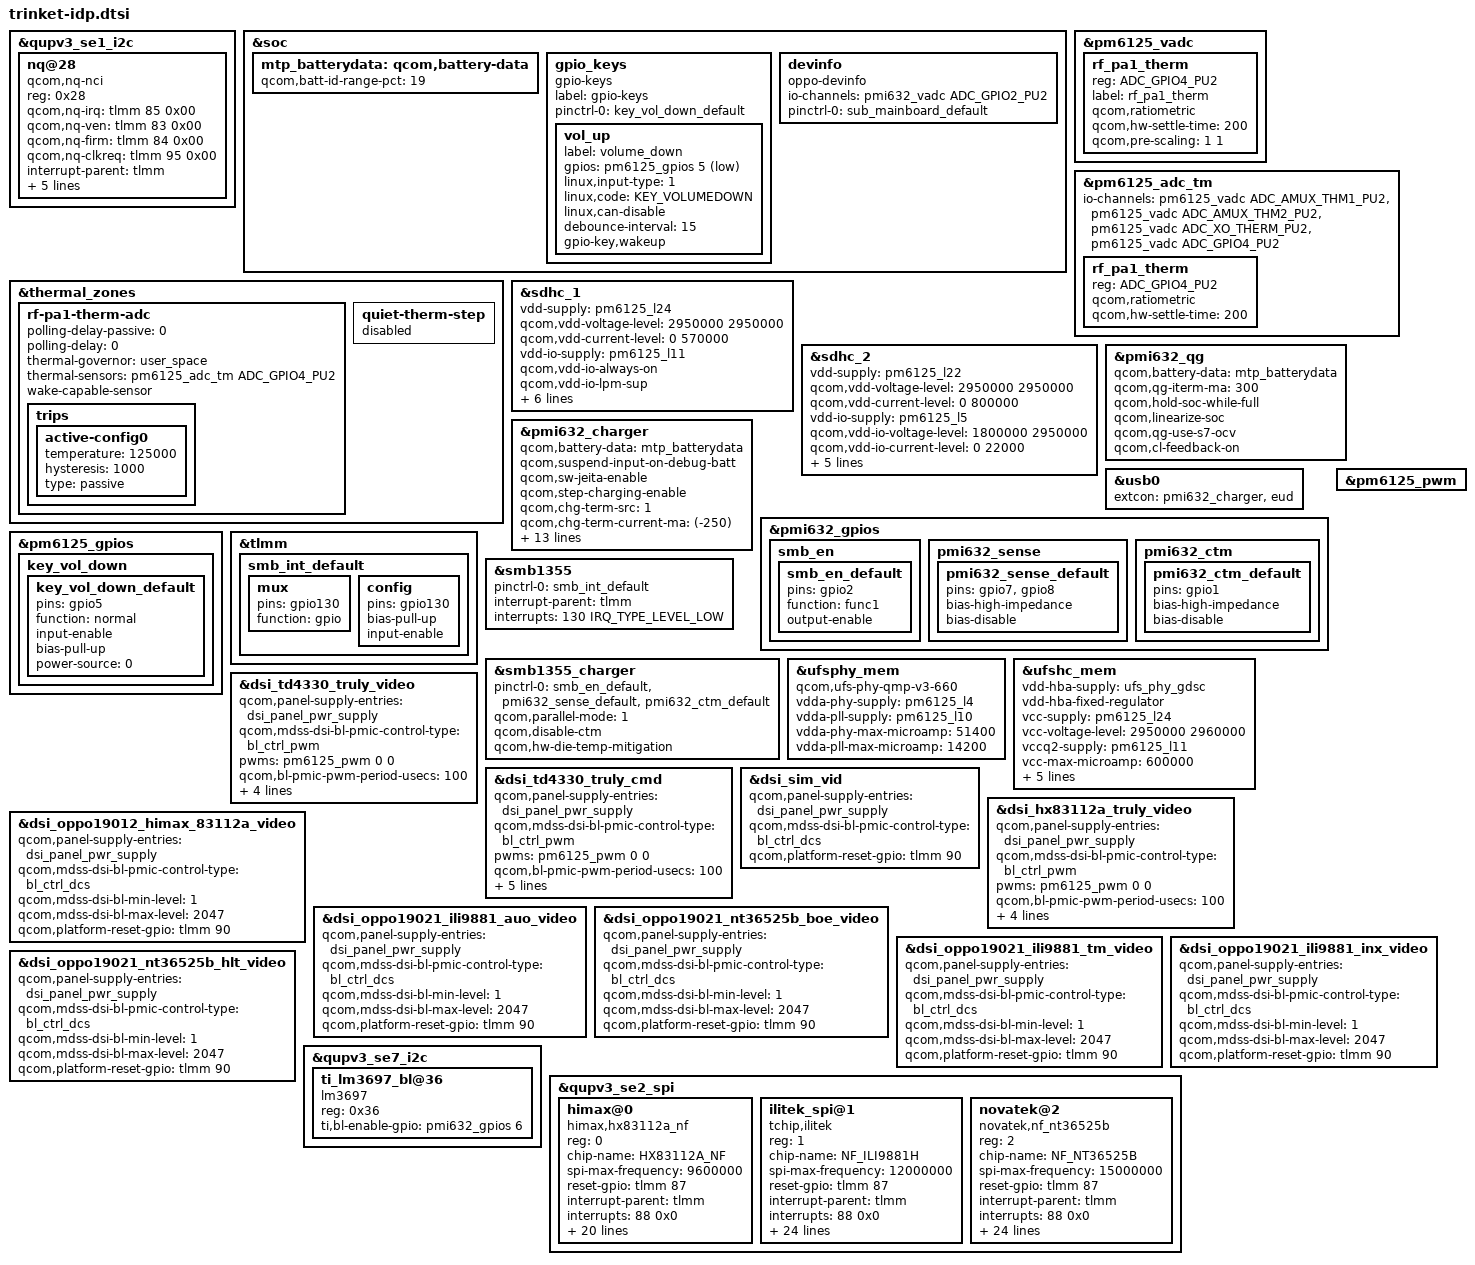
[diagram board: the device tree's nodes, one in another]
/*
 * Copyright (c) 2018-2019, The Linux Foundation. All rights reserved.
 *
 * This program is free software; you can redistribute it and/or modify
 * it under the terms of the GNU General Public License version 2 and
 * only version 2 as published by the Free Software Foundation.
 *
 * This program is distributed in the hope that it will be useful,
 * but WITHOUT ANY WARRANTY; without even the implied warranty of
 * MERCHANTABILITY or FITNESS FOR A PARTICULAR PURPOSE.  See the
 * GNU General Public License for more details.
 */
#include <dt-bindings/gpio/gpio.h>
#include <dt-bindings/input/input.h>
#include <dt-bindings/iio/qcom,spmi-vadc.h>
#include "trinket-thermal-overlay.dtsi"
#include "trinket-sde-display.dtsi"
#include <dt-bindings/clock/qcom,gcc-trinket.h>
#include "trinket-camera-sensor-idp.dtsi"

&qupv3_se1_i2c {
	status = "ok";
	#include "smb1355.dtsi"
};

&soc {
	mtp_batterydata: qcom,battery-data {
//#ifndef VENDOR_EDIT
//		qcom,batt-id-range-pct = <15>;
//#else
        qcom,batt-id-range-pct = <19>;
//#endif
//#ifndef VENDOR_EDIT
//		#include "qg-batterydata-ascent-3450mah.dtsi"
//		#include "qg-batterydata-mlp356477-2800mah.dtsi"
//#else
		#include "oppo_battery_4910mah_68k_pmi632_atl.dtsi"
		#include "oppo_battery_5000mah_470k_pmi632_sdi.dtsi"
		#include "oppo_battery_5000mah_15k_pmi632_cl.dtsi"
//#endif
	};
};

&pm6125_vadc {
	rf_pa1_therm {
		reg = <ADC_GPIO4_PU2>;
		label = "rf_pa1_therm";
		qcom,ratiometric;
		qcom,hw-settle-time = <200>;
		qcom,pre-scaling = <1 1>;
	};
};

&pm6125_adc_tm {
	io-channels = <&pm6125_vadc ADC_AMUX_THM1_PU2>,
			<&pm6125_vadc ADC_AMUX_THM2_PU2>,
			<&pm6125_vadc ADC_XO_THERM_PU2>,
			<&pm6125_vadc ADC_GPIO4_PU2>;

	rf_pa1_therm {
		reg = <ADC_GPIO4_PU2>;
		qcom,ratiometric;
		qcom,hw-settle-time = <200>;
	};
};

&thermal_zones {
	rf-pa1-therm-adc {
		polling-delay-passive = <0>;
		polling-delay = <0>;
		thermal-governor = "user_space";
		thermal-sensors = <&pm6125_adc_tm ADC_GPIO4_PU2>;
		wake-capable-sensor;
		trips {
			active-config0 {
				temperature = <125000>;
				hysteresis = <1000>;
				type = "passive";
			};
		};
	};

	quiet-therm-step {
		status = "disabled";
	};
};

&qupv3_se1_i2c {
	status = "ok";
	nq@28 {
		compatible = "qcom,nq-nci";
		reg = <0x28>;
		qcom,nq-irq = <&tlmm 85 0x00>;
		qcom,nq-ven = <&tlmm 83 0x00>;
		qcom,nq-firm = <&tlmm 84 0x00>;
		qcom,nq-clkreq = <&tlmm 95 0x00>;
		interrupt-parent = <&tlmm>;
		interrupts = <85 0>;
		interrupt-names = "nfc_irq";
		pinctrl-names = "nfc_active", "nfc_suspend";
		pinctrl-0 = <&nfc_int_active &nfc_enable_active
				&nfc_clk_req_active>;
		pinctrl-1 = <&nfc_int_suspend &nfc_enable_suspend
				&nfc_clk_req_suspend>;
	};
};

&sdhc_1 {
	vdd-supply = <&pm6125_l24>;
	qcom,vdd-voltage-level = <2950000 2950000>;
	qcom,vdd-current-level = <0 570000>;

	vdd-io-supply = <&pm6125_l11>;
	qcom,vdd-io-always-on;
	qcom,vdd-io-lpm-sup;
	qcom,vdd-io-voltage-level = <1800000 1800000>;
	qcom,vdd-io-current-level = <0 325000>;

	pinctrl-names = "active", "sleep";
	pinctrl-0 = <&sdc1_clk_on &sdc1_cmd_on &sdc1_data_on
					&sdc1_rclk_on>;
	pinctrl-1 = <&sdc1_clk_off &sdc1_cmd_off &sdc1_data_off
					&sdc1_rclk_off>;

	status = "ok";
};

&sdhc_2 {
	vdd-supply = <&pm6125_l22>;
	qcom,vdd-voltage-level = <2950000 2950000>;
	qcom,vdd-current-level = <0 800000>;

	vdd-io-supply = <&pm6125_l5>;
	qcom,vdd-io-voltage-level = <1800000 2950000>;
	qcom,vdd-io-current-level = <0 22000>;

	pinctrl-names = "active", "sleep";
	pinctrl-0 = <&sdc2_clk_on  &sdc2_cmd_on &sdc2_data_on &sdc2_cd_on>;
	pinctrl-1 = <&sdc2_clk_off &sdc2_cmd_off &sdc2_data_off &sdc2_cd_off>;

	cd-gpios = <&tlmm 98 GPIO_ACTIVE_LOW>;

	status = "ok";
};

&pmi632_qg {
	qcom,battery-data = <&mtp_batterydata>;
	qcom,qg-iterm-ma = <300>;
	qcom,hold-soc-while-full;
	qcom,linearize-soc;
	qcom,qg-use-s7-ocv;
//#ifdef VENDOR_EDIT
	qcom,cl-feedback-on;
//#endif
};

&pmi632_charger {
	qcom,battery-data = <&mtp_batterydata>;
	qcom,suspend-input-on-debug-batt;
	qcom,sw-jeita-enable;
	qcom,step-charging-enable;
	qcom,chg-term-src = <1>;
	qcom,chg-term-current-ma = <(-250)>;
	qcom,chg-term-base-current-ma = <(-200)>;
	/* SMB1355 only */
	qcom,sec-charger-config = <2>;
	dpdm-supply = <&qusb_phy0>;
	qcom,charger-temp-max = <800>;
	qcom,smb-temp-max = <800>;
	qcom,auto-recharge-soc = <98>;
// #ifdef VENDOR_EDIT
    	// qcom,flash-disable-soc = <10>;
// #else
    	qcom,flash-disable-soc = <1>;
// #endif
	qcom,hw-die-temp-mitigation;
	qcom,hw-connector-mitigation;
	qcom,connector-internal-pull-kohm = <100>;
	qcom,float-option = <1>;
	qcom,thermal-mitigation = <3000000 2500000
			2000000 1500000 1000000 500000>;
};

&usb0 {
	extcon = <&pmi632_charger>, <&eud>;
};

&pmi632_gpios {
	smb_en {
		smb_en_default: smb_en_default {
			pins = "gpio2";
			function = "func1";
			output-enable;
		};
	};

	pmi632_sense {
		/* GPIO 7 and 8 are external-sense pins for PMI632 */
		pmi632_sense_default: pmi632_sense_default {
			pins = "gpio7", "gpio8";
			bias-high-impedance;	/* disable the GPIO */
			bias-disable;		/* no-pull */
		};
	};

	pmi632_ctm {
		/* Disable GPIO1 for h/w base mitigation */
		pmi632_ctm_default: pmi632_ctm_default {
			pins = "gpio1";
			bias-high-impedance;	/* disable the GPIO */
			bias-disable;		/* no-pull */
		};
	};
};

&pm6125_gpios {
	//#ifndef VENDOR_EDIT
	//key_vol_up {
	//	key_vol_up_default: key_vol_up_default {
	//		pins = "gpio5";
	//		function = "normal";
	//		input-enable;
	//		bias-pull-up;
	//		power-source = <0>;
	//	};
	//};
	//#else
	key_vol_down {
		key_vol_down_default: key_vol_down_default {
			pins = "gpio5";
			function = "normal";
			input-enable;
			bias-pull-up;
			power-source = <0>;
		};
	};
	//#endif
};

&soc {
	gpio_keys {
		compatible = "gpio-keys";
		label = "gpio-keys";

		pinctrl-names = "default";

		//#ifndef VENDOR_EDIT
		//pinctrl-0 = <&key_vol_up_default>;
		//vol_up {
		//	label = "volume_up";
		//	gpios = <&pm6125_gpios 5 GPIO_ACTIVE_LOW>;
		//	linux,input-type = <1>;
		//	linux,code = <KEY_VOLUMEUP>;
		//	linux,can-disable;
		//	debounce-interval = <15>;
		//	gpio-key,wakeup;
		//};
		//#else
		pinctrl-0 = <&key_vol_down_default>;
		vol_up {
			label = "volume_down";
			gpios = <&pm6125_gpios 5 GPIO_ACTIVE_LOW>;
			linux,input-type = <1>;
			linux,code = <KEY_VOLUMEDOWN>;
			linux,can-disable;
			debounce-interval = <15>;
			gpio-key,wakeup;
		};
		//#endif
	};

	/*ifdef VENDOR_EDIT*/
	devinfo {
		compatible = "oppo-devinfo";
		io-channel-names = "sub_adc_gpio3";
		io-channels = <&pmi632_vadc ADC_GPIO2_PU2>;
		pinctrl-names = "default";
		pinctrl-0 = <&sub_mainboard_default>;
	};
	/*endif*/
};

&tlmm {
	smb_int_default: smb_int_default {
		mux {
			pins = "gpio130";
			function = "gpio";
		};
		config {
			pins = "gpio130";
			bias-pull-up;
			input-enable;
		};
	};
};

&smb1355 {
	pinctrl-names = "default";
	pinctrl-0 = <&smb_int_default>;
	interrupt-parent = <&tlmm>;
	interrupts = <130 IRQ_TYPE_LEVEL_LOW>;
	status = "ok";
};

&smb1355_charger {
	pinctrl-names = "default";
	pinctrl-0 = <&smb_en_default &pmi632_sense_default &pmi632_ctm_default>;
	qcom,parallel-mode = <1>;
	qcom,disable-ctm;
	qcom,hw-die-temp-mitigation;
	status = "ok";
};

&ufsphy_mem {
	compatible = "qcom,ufs-phy-qmp-v3-660";

	vdda-phy-supply = <&pm6125_l4>; /* 0.9v */
	vdda-pll-supply = <&pm6125_l10>; /* 1.8v */
	vdda-phy-max-microamp = <51400>;
	vdda-pll-max-microamp = <14200>;

	status = "ok";
};

&ufshc_mem {
	vdd-hba-supply = <&ufs_phy_gdsc>;
	vdd-hba-fixed-regulator;
	vcc-supply = <&pm6125_l24>;
	vcc-voltage-level = <2950000 2960000>;
	vccq2-supply = <&pm6125_l11>;
	vcc-max-microamp = <600000>;
	vccq2-max-microamp = <600000>;

	qcom,vddp-ref-clk-supply = <&pm6125_l18>;
	qcom,vddp-ref-clk-max-microamp = <100>;
	qcom,vddp-ref-clk-min-uV = <1200000>;
	qcom,vddp-ref-clk-max-uV = <1232000>;

	status = "ok";
};

&pm6125_pwm {
	status = "ok";
};

&dsi_td4330_truly_video {
	qcom,panel-supply-entries = <&dsi_panel_pwr_supply>;
	qcom,mdss-dsi-bl-pmic-control-type = "bl_ctrl_pwm";
	pwms = <&pm6125_pwm 0 0>;
	qcom,bl-pmic-pwm-period-usecs = <100>;
	qcom,mdss-dsi-bl-min-level = <1>;
	qcom,mdss-dsi-bl-max-level = <4095>;
	qcom,platform-reset-gpio = <&tlmm 90 0>;
	qcom,platform-bklight-en-gpio = <&pmi632_gpios 6 0>;
};

&dsi_td4330_truly_cmd {
	qcom,panel-supply-entries = <&dsi_panel_pwr_supply>;
	qcom,mdss-dsi-bl-pmic-control-type = "bl_ctrl_pwm";
	pwms = <&pm6125_pwm 0 0>;
	qcom,bl-pmic-pwm-period-usecs = <100>;
	qcom,mdss-dsi-bl-min-level = <1>;
	qcom,mdss-dsi-bl-max-level = <4095>;
	qcom,platform-te-gpio = <&tlmm 89 0>;
	qcom,platform-reset-gpio = <&tlmm 90 0>;
	qcom,platform-bklight-en-gpio = <&pmi632_gpios 6 0>;
};

&dsi_sim_vid {
	qcom,panel-supply-entries = <&dsi_panel_pwr_supply>;
	qcom,mdss-dsi-bl-pmic-control-type = "bl_ctrl_dcs";
	qcom,platform-reset-gpio = <&tlmm 90 0>;
};

&dsi_hx83112a_truly_video {
	qcom,panel-supply-entries = <&dsi_panel_pwr_supply>;
	qcom,mdss-dsi-bl-pmic-control-type = "bl_ctrl_pwm";
	pwms = <&pm6125_pwm 0 0>;
	qcom,bl-pmic-pwm-period-usecs = <100>;
	qcom,mdss-dsi-bl-min-level = <1>;
	qcom,mdss-dsi-bl-max-level = <4095>;
	qcom,platform-reset-gpio = <&tlmm 90 0>;
	qcom,platform-bklight-en-gpio = <&pmi632_gpios 6 0>;
};


//ifdef VENDOR_EDIT
&dsi_oppo19012_himax_83112a_video {
	qcom,panel-supply-entries = <&dsi_panel_pwr_supply>;
	qcom,mdss-dsi-bl-pmic-control-type = "bl_ctrl_dcs";
	qcom,mdss-dsi-bl-min-level = <1>;
	qcom,mdss-dsi-bl-max-level = <2047>;
	//qcom,platform-te-gpio = <&tlmm 89 0>;
	qcom,platform-reset-gpio = <&tlmm 90 0>;
	//qcom,platform-bklight-en-gpio = <&pmi632_gpios 6 0>;
	//qcom,platform-lcd-1v8-en-gpio = <&pmi632_gpios 4 0>;
};


&dsi_oppo19021_ili9881_auo_video {
	qcom,panel-supply-entries = <&dsi_panel_pwr_supply>;
	qcom,mdss-dsi-bl-pmic-control-type = "bl_ctrl_dcs";
	qcom,mdss-dsi-bl-min-level = <1>;
	qcom,mdss-dsi-bl-max-level = <2047>;
	//qcom,platform-te-gpio = <&tlmm 89 0>;
	qcom,platform-reset-gpio = <&tlmm 90 0>;
	//qcom,platform-bklight-en-gpio = <&pmi632_gpios 6 0>;
	//qcom,platform-lcd-1v8-en-gpio = <&pmi632_gpios 4 0>;
};

&dsi_oppo19021_nt36525b_boe_video {
	qcom,panel-supply-entries = <&dsi_panel_pwr_supply>;
	qcom,mdss-dsi-bl-pmic-control-type = "bl_ctrl_dcs";
	qcom,mdss-dsi-bl-min-level = <1>;
	qcom,mdss-dsi-bl-max-level = <2047>;
	//qcom,platform-te-gpio = <&tlmm 89 0>;
	qcom,platform-reset-gpio = <&tlmm 90 0>;
	//qcom,platform-bklight-en-gpio = <&pmi632_gpios 6 0>;
	//qcom,platform-lcd-1v8-en-gpio = <&pmi632_gpios 4 0>;
};

&dsi_oppo19021_ili9881_tm_video {
	qcom,panel-supply-entries = <&dsi_panel_pwr_supply>;
	qcom,mdss-dsi-bl-pmic-control-type = "bl_ctrl_dcs";
	qcom,mdss-dsi-bl-min-level = <1>;
	qcom,mdss-dsi-bl-max-level = <2047>;
	//qcom,platform-te-gpio = <&tlmm 89 0>;
	qcom,platform-reset-gpio = <&tlmm 90 0>;
	//qcom,platform-bklight-en-gpio = <&pmi632_gpios 6 0>;
	//qcom,platform-lcd-1v8-en-gpio = <&pmi632_gpios 4 0>;
};

&dsi_oppo19021_ili9881_inx_video {
	qcom,panel-supply-entries = <&dsi_panel_pwr_supply>;
	qcom,mdss-dsi-bl-pmic-control-type = "bl_ctrl_dcs";
	qcom,mdss-dsi-bl-min-level = <1>;
	qcom,mdss-dsi-bl-max-level = <2047>;
	//qcom,platform-te-gpio = <&tlmm 89 0>;
	qcom,platform-reset-gpio = <&tlmm 90 0>;
	//qcom,platform-bklight-en-gpio = <&pmi632_gpios 6 0>;
	//qcom,platform-lcd-1v8-en-gpio = <&pmi632_gpios 4 0>;
};

&dsi_oppo19021_nt36525b_hlt_video {
	qcom,panel-supply-entries = <&dsi_panel_pwr_supply>;
	qcom,mdss-dsi-bl-pmic-control-type = "bl_ctrl_dcs";
	qcom,mdss-dsi-bl-min-level = <1>;
	qcom,mdss-dsi-bl-max-level = <2047>;
	//qcom,platform-te-gpio = <&tlmm 89 0>;
	qcom,platform-reset-gpio = <&tlmm 90 0>;
	//qcom,platform-bklight-en-gpio = <&pmi632_gpios 6 0>;
	//qcom,platform-lcd-1v8-en-gpio = <&pmi632_gpios 4 0>;
};
//endif
//ifdef VENDOR_EDIT
&qupv3_se7_i2c {
	status = "ok";
	ti_lm3697_bl@36 {
		compatible = "lm3697";
		reg = <0x36>;
		ti,bl-enable-gpio = <&pmi632_gpios 6 0>;
	};
};
//endif

&dsi_oppo19021_ili9881_tm_video {
	qcom,panel-supply-entries = <&dsi_panel_pwr_supply>;
	qcom,mdss-dsi-bl-pmic-control-type = "bl_ctrl_dcs";
	qcom,mdss-dsi-bl-min-level = <1>;
	qcom,mdss-dsi-bl-max-level = <2047>;
	//qcom,platform-te-gpio = <&tlmm 89 0>;
	qcom,platform-reset-gpio = <&tlmm 90 0>;
	//qcom,platform-bklight-en-gpio = <&pmi632_gpios 6 0>;
	//qcom,platform-lcd-1v8-en-gpio = <&pmi632_gpios 4 0>;
};

&dsi_oppo19021_ili9881_inx_video {
	qcom,panel-supply-entries = <&dsi_panel_pwr_supply>;
	qcom,mdss-dsi-bl-pmic-control-type = "bl_ctrl_dcs";
	qcom,mdss-dsi-bl-min-level = <1>;
	qcom,mdss-dsi-bl-max-level = <2047>;
	//qcom,platform-te-gpio = <&tlmm 89 0>;
	qcom,platform-reset-gpio = <&tlmm 90 0>;
	//qcom,platform-bklight-en-gpio = <&pmi632_gpios 6 0>;
	//qcom,platform-lcd-1v8-en-gpio = <&pmi632_gpios 4 0>;
};

&dsi_oppo19021_nt36525b_hlt_video {
	qcom,panel-supply-entries = <&dsi_panel_pwr_supply>;
	qcom,mdss-dsi-bl-pmic-control-type = "bl_ctrl_dcs";
	qcom,mdss-dsi-bl-min-level = <1>;
	qcom,mdss-dsi-bl-max-level = <2047>;
	//qcom,platform-te-gpio = <&tlmm 89 0>;
	qcom,platform-reset-gpio = <&tlmm 90 0>;
	//qcom,platform-bklight-en-gpio = <&pmi632_gpios 6 0>;
	//qcom,platform-lcd-1v8-en-gpio = <&pmi632_gpios 4 0>;
};
//endif
//ifdef VENDOR_EDIT
&qupv3_se7_i2c {
	status = "ok";
	ti_lm3697_bl@36 {
		compatible = "lm3697";
		reg = <0x36>;
		ti,bl-enable-gpio = <&pmi632_gpios 6 0>;
	};
};
//endif
//#ifdef VENDOR_EDIT
&qupv3_se2_spi {
	/* Himax device tree node */
	status = "ok";
	himax@0 {
		compatible = "himax,hx83112a_nf";
		reg = <0>;
		chip-name = "HX83112A_NF";
		status = "ok";

		spi-max-frequency = <9600000>;    //4800000,9600000,15000000,19200000
		reset-gpio = <&tlmm 87 0x00>;
		interrupt-parent = <&tlmm>;
		interrupts = <88 0x0>;
		irq-gpio = <&tlmm 88 0x2001>;

		touchpanel,max-num-support = <10>;
		touchpanel,tx-rx-num = <18 36>;
		touchpanel,panel-coords = <1080 2340>;
		touchpanel,display-coords = <1080 2340>;
				touchpanel,touchmajor-limit = <0 54>;

		pinctrl-names = "default", "suspend";
		pinctrl-0 = <&ts_int_active &ts_reset_active>;
		pinctrl-1 = <&ts_int_suspend &ts_reset_suspend>;

		incell_screen;
		fw_edge_limit_support;
		black_gesture_support;
		charger_pump_support;
		//headset_pump_support;
		esd_handle_support;
		//spurious_fingerprint_support;
		//lcd_trigger_fp_check;
		black_gesture_test_support;
		noflash_support;
		smart_gesture_support;
		//fw_update_app_support;
		game_switch_support;
		drlimit_remove_support;
		//lcd_trigger_load_tp_fw_support;
		fw_update_in_probe_with_headfile;

		touchpanel,button-type = <4>;
	};
	ilitek_spi@1 {
		compatible = "tchip,ilitek";
		reg = <1>;
		chip-name = "NF_ILI9881H";
		status = "ok";

		spi-max-frequency = <12000000>;    //4800000,9600000,15000000,19200000
		reset-gpio = <&tlmm 87 0x00>;
		interrupt-parent = <&tlmm>;
		interrupts = <88 0x0>;
		irq-gpio = <&tlmm 88 0x2002>;

		touchpanel,max-num-support = <10>;
		touchpanel,tx-rx-num = <18 32>;
		touchpanel,panel-coords = <720 1600>;
		touchpanel,display-coords = <720 1600>;
				touchpanel,touchmajor-limit = <0 54>;

		pinctrl-names = "default", "suspend";
		pinctrl-0 = <&ts_int_active &ts_reset_active>;
		pinctrl-1 = <&ts_int_suspend &ts_reset_suspend>;

		incell_screen;
		fw_edge_limit_support;
		black_gesture_support;
		charger_pump_support;
		headset_pump_support;
		esd_handle_support;
		//spurious_fingerprint_support;
		//lcd_trigger_fp_check;
		black_gesture_test_support;
		noflash_support;
		smart_gesture_support;
		pressure_report_support;
		fw_update_app_support;
		game_switch_support;
		drlimit_remove_support;
		lcd_trigger_load_tp_fw_support;
		suspend_gesture_cfg;
		//fw_update_in_probe_with_headfile;

		touchpanel,button-type = <4>;
	};
	novatek@2 {
		compatible = "novatek,nf_nt36525b";
		reg = <2>;
		chip-name = "NF_NT36525B";
		status = "ok";

		spi-max-frequency = <15000000>;	//4800000,9600000,15000000,19200000
		reset-gpio = <&tlmm 87 0x00>;
		interrupt-parent = <&tlmm>;
		interrupts = <88 0x0>;
		irq-gpio = <&tlmm 88 0x2002>;
		lcd-reset-gpio = <&tlmm 90 0x00>;

		touchpanel,max-num-support = <10>;
		touchpanel,tx-rx-num = <18 32>;
		touchpanel,panel-coords = <720 1600>;
		touchpanel,display-coords = <720 1600>;
				touchpanel,touchmajor-limit = <0 54>;

		pinctrl-names = "default", "suspend";
		pinctrl-0 = <&ts_int_active &ts_reset_active>;
		pinctrl-1 = <&ts_int_suspend &ts_reset_suspend>;

		incell_screen;
		fw_edge_limit_support;
		black_gesture_support;
		charger_pump_support;
		headset_pump_support;
		esd_handle_support;
		//spurious_fingerprint_support;
		//lcd_trigger_fp_check;
		black_gesture_test_support;
		noflash_support;
		smart_gesture_support;
		pressure_report_support;
		fw_update_app_support;
		game_switch_support;
		drlimit_remove_support;
		lcd_trigger_load_tp_fw_support;
		//fw_update_in_probe_with_headfile;

		touchpanel,button-type = <4>;
	};
};
//#endif
